# iomux_secure register map
Vendor: Texas Instruments
Peripheral module from a debugger description file (folder CC35X1).
Registers are 32-bit, access per field, reset 0x0 unless marked. A register's access mark holds for its fields unless they carry their own. Offsets are as the file gives them; lines under a group give offsets from that group; [hi:lo] are bit positions; {n}, {i} and the like mark numbered series; 'fields as' and 'values as' point back to an identical list; <NAME> marks a mode.

## iomux_secure (part 1 of 2)
0x00 ctl0_slow_clock_in reset 0x800 — CFG register for IO SLOW_CLOCK_IN. This register configures the corresponding pad
  [11] IE rw — This field enables the receiver operation from the pad
    0=DISABLE (Disable the receiver operation); 1=ENABLE (Enable the receiver operation)
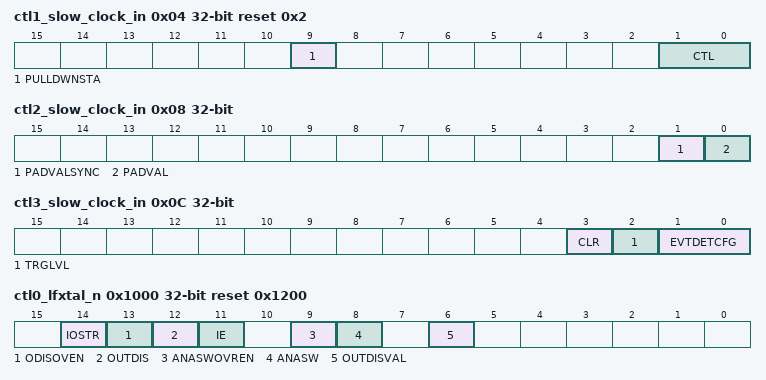
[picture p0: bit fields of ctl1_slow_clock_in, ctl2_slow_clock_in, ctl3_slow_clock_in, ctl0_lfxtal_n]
0x04 ctl1_slow_clock_in reset 0x2 — Pull control register of IO SLOW_CLOCK_IN This register configures the pull control
  [9] PULLDWNSTA ro — This field gives the IO pull down level status
    0=CLEAR (Pull disabled); 1=SET (Pull down)
  [1:0] CTL rw — The fields defines the pull control
    0=IPCTRL (IP Pull Control); 2=UP (Pull up); 3=DISABLE (Pull disable)
0x08 ctl2_slow_clock_in ro — Control register of IO SLOW_CLOCK_IN This register controls the IO state
  [1] PADVALSYNC — This field captures the synchronized(to SOC clock) received value
  [0] PADVAL — This field captures the received value from pad
0x0C ctl3_slow_clock_in — Event control register for IO SLOW_CLOCK_IN This register controls the Event configuration and behavior
  [3] CLR wo — This bit is to be used to generate CLR pulse for the event
    0=NOEFF (No effect); 1=CLEAR (Clear the event)
  [2] TRGLVL rw — This field configures the io event polarity. This field is applicable only when [EVTDETCFG] is configured LEVEL
    0=HIGH (Non Inverted polarity); 1=LOW (Inverted polarity)
  [1:0] EVTDETCFG rw — This field is to be configured to define the IO detection method
    0=MASK (Masking the event); 1=POS_EDGE (Rising edge/Positive edge detection); 2=NEG_EDGE (Falling edge/Negative edge detection); 3=LEVEL (Level detection)
0x1000 ctl0_lfxtal_n reset 0x1200 — CFG register for IO LFXTAL_N. This register configures the corresponding pad
  [14] IOSTR rw — This field controls the IO drive strength
    0=LOW (IO drives low power); 1=HIGH (IO drives high power)
  [13] ODISOVEN rw — This field controls the [OUTDIS] override
    0=DISABLE (Disable the override); 1=ENABLE (Enable the override)
  [12] OUTDIS rw — This field configures the output from the pad Note:This field is applicable only if [OUTDISOVREN] is enabled
    1=SET (Output from the pad is disabled); 0=CLEAR (Output from the pad is enabled)
  [11] IE rw — This field enables the receiver operation from the pad
    values as ctl0_slow_clock_in.IE
  [9] ANASWOVREN rw — This field controls the analog switch override
    0=DISABLE (Analog switch is controlled by IP); 1=ENABLE (Enable override on analog switch control)
  [8] ANASW rw — This field defines the Ana switch state. If the switch is enabled, the analog signal is routed to the IO pad Note: This field is applicable when [ANASWOVREN] is enabled
    0=DISABLE (Analog switch open); 1=ENABLE (Analog switch closed)
  [6] OUTDISVAL ro — The field gives the status of [OUTDIS]
    0=CLEAR (Output is enabled); 1=SET (Output is disabled)
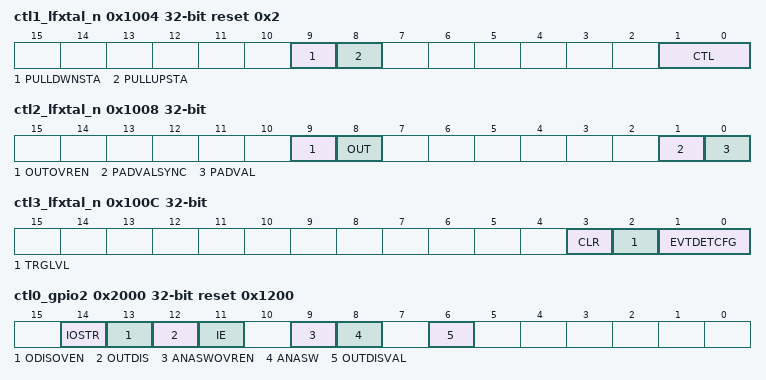
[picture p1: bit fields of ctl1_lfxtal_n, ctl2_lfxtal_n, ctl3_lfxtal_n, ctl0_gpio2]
0x1004 ctl1_lfxtal_n reset 0x2 — Pull control register of IO LFXTAL_N This register configures the pull control
  [9] PULLDWNSTA ro — This field gives the IO pull down level status
    0=CLEAR (Pull disabled); 1=SET (Pull down)
  [8] PULLUPSTA ro — This field gives the IO pull up level status
    0=CLEAR (Pull disabled); 1=SET (Pull up)
  [1:0] CTL rw — The fields defines the pull control
    0=IPCTRL (IP Pull Control); 1=DOWN (Pull down); 2=UP (Pull up); 3=DISABLE (Pull disable)
0x1008 ctl2_lfxtal_n — Control register of IO LFXTAL_N This register controls the IO state
  [9] OUTOVREN rw — This field controls the override on output
    0=DISABLE (Output controlled by IP); 1=ENABLE (Enable override on output)
  [8] OUT rw — This field configures the IO drive out value. This field is valid only when [OUTOVREN] is configured ENABLE
    0=LOW (IO drives 0); 1=HIGH (IO drives 1)
  [1] PADVALSYNC ro — This field captures the synchronized(to SOC clock) received value
  [0] PADVAL ro — This field captures the received value from pad
0x100C ctl3_lfxtal_n — Event control register for IO LFXTAL_N This register controls the Event configuration and behavior
  fields as ctl3_slow_clock_in
0x2000 ctl0_gpio2 reset 0x1200 — CFG register for IO GPIO2. This register configures the corresponding pad
  [14] IOSTR rw — This field controls the IO drive strength
    0=LOW (IO drives low power); 1=HIGH (IO drives high power)
  [13] ODISOVEN rw — This field controls the [OUTDIS] override
    values as ctl0_lfxtal_n.ODISOVEN
  [12] OUTDIS rw — This field configures the output from the pad Note:This field is applicable only if [OUTDISOVREN] is enabled
    1=SET (Output from the pad is disabled); 0=ENABLE (Output from the pad is enabled)
  [11] IE rw — This field enables the receiver operation from the pad
    values as ctl0_slow_clock_in.IE
  [9] ANASWOVREN rw — This field controls the analog switch override
    values as ctl0_lfxtal_n.ANASWOVREN
  [8] ANASW rw — This field defines the Ana switch state. If the switch is enabled, the analog signal is routed to the IO pad Note: This field is applicable when [ANASWOVREN] is enabled
    values as ctl0_lfxtal_n.ANASW
  [6] OUTDISVAL ro — The field gives the status of [OUTDIS]
    0=CLEAR (Output is enabled); 1=SET (Output is disabled)
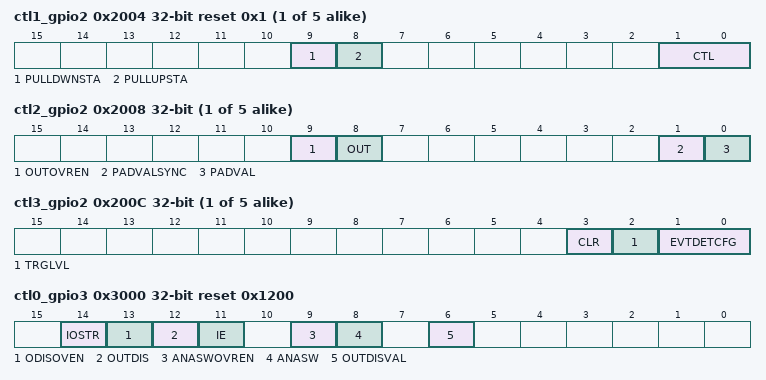
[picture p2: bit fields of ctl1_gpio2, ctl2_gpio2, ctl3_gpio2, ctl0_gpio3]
{0x4+0x1000*i} ctl1_gpio{i} reset 0x1 (i=2..6) — Pull control register of IO GPIO{i} This register configures the pull control
  fields as ctl1_lfxtal_n
{0x8+0x1000*i} ctl2_gpio{i} (i=2..6) — Control register of IO GPIO{i} This register controls the IO state
  fields as ctl2_lfxtal_n
{0xC+0x1000*i} ctl3_gpio{i} (i=2..6) — Event control register for IO GPIO{i} This register controls the Event configuration and behavior
  fields as ctl3_slow_clock_in
0x3000 ctl0_gpio3 reset 0x1200 — CFG register for IO GPIO3. This register configures the corresponding pad
  fields as ctl0_lfxtal_n
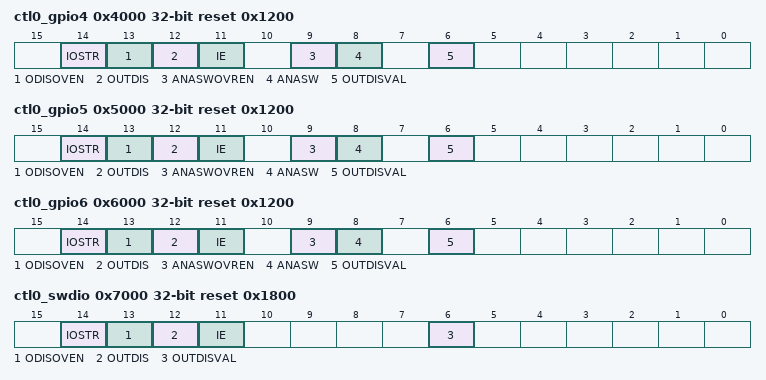
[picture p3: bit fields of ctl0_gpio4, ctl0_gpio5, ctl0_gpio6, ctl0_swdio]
0x4000 ctl0_gpio4 reset 0x1200 — CFG register for IO GPIO4. This register configures the corresponding pad
  [14] IOSTR rw — This field controls the IO drive strength
    0=LOW (IO drives low power); 1=HIGH (IO drives high power)
  [13] ODISOVEN rw — This field controls the [OUTDIS] override
    values as ctl0_lfxtal_n.ODISOVEN
  [12] OUTDIS rw — This field configures the output from the pad Note:This field is applicable only if [OUTDISOVREN] is enabled
    1=DISABLE (Output from the pad is disabled); 0=ENABLE (Output from the pad is enabled)
  [11] IE rw — This field enables the receiver operation from the pad
    values as ctl0_slow_clock_in.IE
  [9] ANASWOVREN rw — This field controls the analog switch override
    values as ctl0_lfxtal_n.ANASWOVREN
  [8] ANASW rw — This field defines the Ana switch state. If the switch is enabled, the analog signal is routed to the IO pad Note: This field is applicable when [ANASWOVREN] is enabled
    values as ctl0_lfxtal_n.ANASW
  [6] OUTDISVAL ro — The field gives the status of [OUTDIS]
    0=CLEAR (Output is enabled); 1=SET (Output is disabled)
0x5000 ctl0_gpio5 reset 0x1200 — CFG register for IO GPIO5. This register configures the corresponding pad
  fields as ctl0_lfxtal_n
0x6000 ctl0_gpio6 reset 0x1200 — CFG register for IO GPIO6. This register configures the corresponding pad
  fields as ctl0_lfxtal_n
0x7000 ctl0_swdio reset 0x1800 — CFG register for IO SWDIO. This register configures the corresponding pad
  [14] IOSTR rw — This field controls the IO drive strength
    0=LOW (IO drives low power); 1=HIGH (IO drives high power)
  [13] ODISOVEN rw — This field controls the [OUTDIS] override
    values as ctl0_lfxtal_n.ODISOVEN
  [12] OUTDIS rw — This field configures the output from the pad Note:This field is applicable only if [OUTDISOVREN] is enabled
    values as ctl0_lfxtal_n.OUTDIS
  [11] IE rw — This field enables the receiver operation from the pad
    values as ctl0_slow_clock_in.IE
  [6] OUTDISVAL ro — The field gives the status of [OUTDIS]
    0=CLEAR (Output is enabled); 1=SET (Output is disabled)
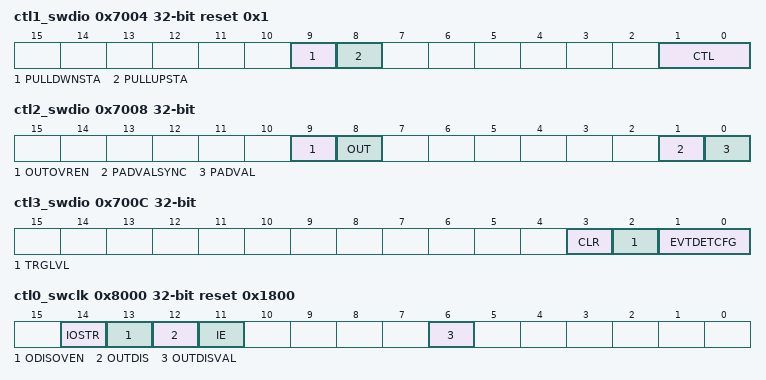
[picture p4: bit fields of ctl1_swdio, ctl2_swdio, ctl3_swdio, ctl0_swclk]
0x7004 ctl1_swdio reset 0x1 — Pull control register of IO SWDIO This register configures the pull control
  fields as ctl1_lfxtal_n
0x7008 ctl2_swdio — Control register of IO SWDIO This register controls the IO state
  fields as ctl2_lfxtal_n
0x700C ctl3_swdio — Event control register for IO SWDIO This register controls the Event configuration and behavior
  fields as ctl3_slow_clock_in
0x8000 ctl0_swclk reset 0x1800 — CFG register for IO SWCLK. This register configures the corresponding pad
  [14] IOSTR rw — This field controls the IO drive strength
    0=LOW (IO drives low power); 1=HIGH (IO drives high power)
  [13] ODISOVEN rw — This field controls the [OUTDIS] override
    values as ctl0_lfxtal_n.ODISOVEN
  [12] OUTDIS rw — This field configures the output from the pad Note:This field is applicable only if [OUTDISOVREN] is enabled
    values as ctl0_gpio4.OUTDIS
  [11] IE rw — This field enables the receiver operation from the pad
    values as ctl0_slow_clock_in.IE
  [6] OUTDISVAL ro — The field gives the status of [OUTDIS]
    0=SET (Output is enabled); 1=CLEAR (Output is disabled)
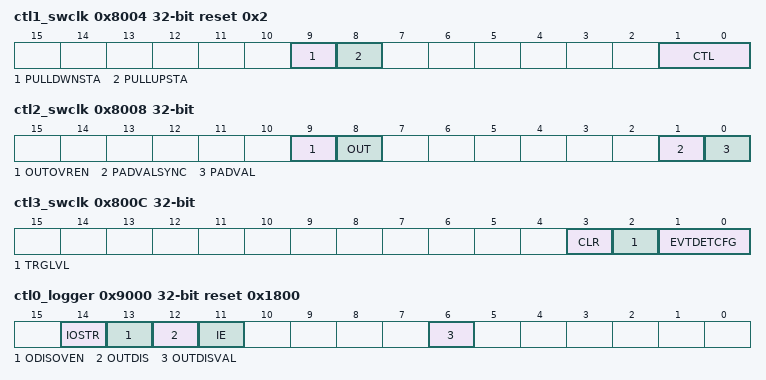
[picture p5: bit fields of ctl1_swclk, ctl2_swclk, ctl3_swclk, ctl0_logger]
0x8004 ctl1_swclk reset 0x2 — Pull control register of IO SWCLK This register configures the pull control
  fields as ctl1_lfxtal_n
0x8008 ctl2_swclk — Control register of IO SWCLK This register controls the IO state
  fields as ctl2_lfxtal_n
0x800C ctl3_swclk — Event control register for IO SWCLK This register controls the Event configuration and behavior
  fields as ctl3_slow_clock_in
0x9000 ctl0_logger reset 0x1800 — CFG register for IO LOGGER. This register configures the corresponding pad
  fields as ctl0_swdio
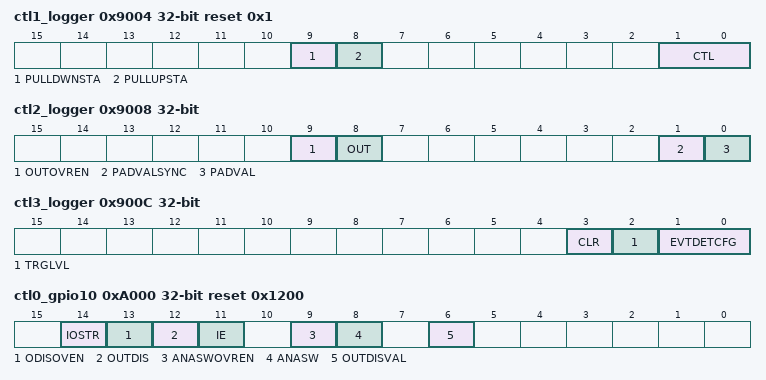
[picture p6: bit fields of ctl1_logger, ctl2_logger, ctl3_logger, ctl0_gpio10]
0x9004 ctl1_logger reset 0x1 — Pull control register of IO LOGGER This register configures the pull control
  fields as ctl1_lfxtal_n
0x9008 ctl2_logger — Control register of IO LOGGER This register controls the IO state
  fields as ctl2_lfxtal_n
0x900C ctl3_logger — Event control register for IO LOGGER This register controls the Event configuration and behavior
  fields as ctl3_slow_clock_in
0xA000 ctl0_gpio10 reset 0x1200 — CFG register for IO GPIO10. This register configures the corresponding pad
  fields as ctl0_lfxtal_n
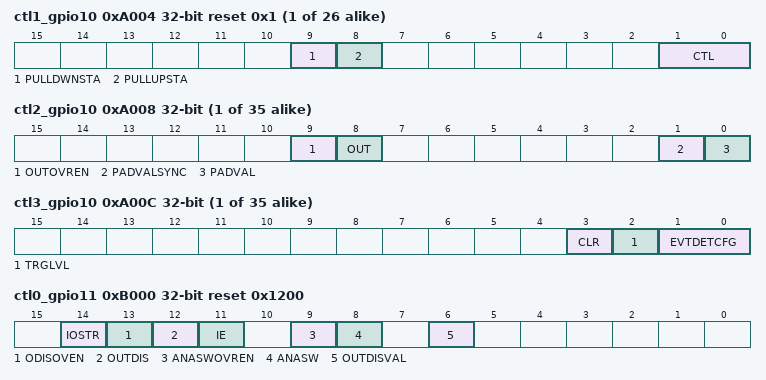
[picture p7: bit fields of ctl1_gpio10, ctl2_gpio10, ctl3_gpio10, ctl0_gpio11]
{0x4+0x1000*i} ctl1_gpio{i} reset 0x1 (i=10..35) — Pull control register of IO GPIO{i} This register configures the pull control
  fields as ctl1_lfxtal_n
{0x8+0x1000*i} ctl2_gpio{i} (i=10..44) — Control register of IO GPIO{i} This register controls the IO state
  fields as ctl2_lfxtal_n
{0xC+0x1000*i} ctl3_gpio{i} (i=10..44) — Event control register for IO GPIO{i} This register controls the Event configuration and behavior
  fields as ctl3_slow_clock_in
0xB000 ctl0_gpio11 reset 0x1200 — CFG register for IO GPIO11. This register configures the corresponding pad
  fields as ctl0_lfxtal_n
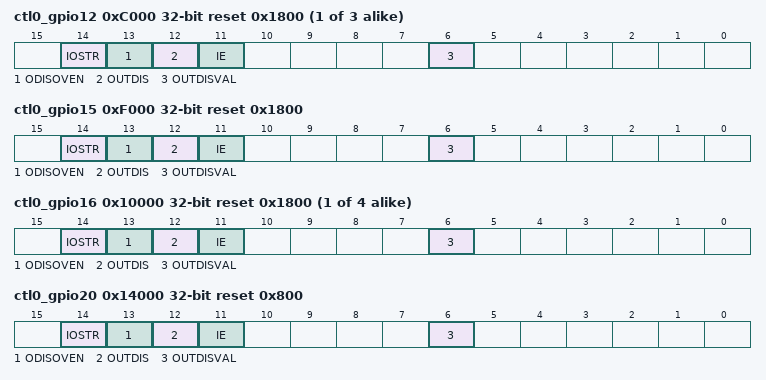
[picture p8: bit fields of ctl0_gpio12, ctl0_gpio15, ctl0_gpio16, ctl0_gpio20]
{0x0+0x1000*i} ctl0_gpio{i} reset 0x1800 (i=12..14) — CFG register for IO GPIO{i}. This register configures the corresponding pad
  fields as ctl0_swdio
0xF000 ctl0_gpio15 reset 0x1800 — CFG register for IO GPIO15. This register configures the corresponding pad
  [14] IOSTR rw — This field controls the IO drive strength
    0=LOW (IO drives low power); 1=HIGH (IO drives high power)
  [13] ODISOVEN rw — This field controls the [OUTDIS] override
    values as ctl0_lfxtal_n.ODISOVEN
  [12] OUTDIS rw — This field configures the output from the pad Note:This field is applicable only if [OUTDISOVREN] is enabled
    values as ctl0_lfxtal_n.OUTDIS
  [11] IE rw — This field enables the receiver operation from the pad
    values as ctl0_slow_clock_in.IE
  [6] OUTDISVAL ro — The field gives the status of [OUTDIS]
    0=SET (Output is enabled); 1=CLEAR (Output is disabled)
{0x0+0x1000*i} ctl0_gpio{i} reset 0x1800 (i=16..19) — CFG register for IO GPIO{i}. This register configures the corresponding pad
  fields as ctl0_swdio
0x14000 ctl0_gpio20 reset 0x800 — CFG register for IO GPIO20. This register configures the corresponding pad
  fields as ctl0_swdio
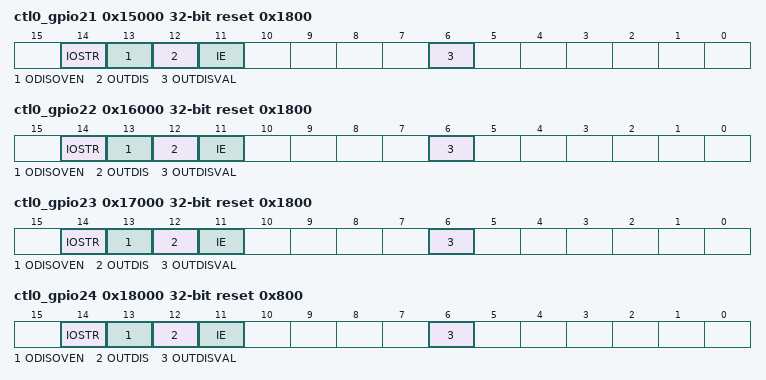
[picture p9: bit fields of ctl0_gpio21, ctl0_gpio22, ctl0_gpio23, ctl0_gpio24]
0x15000 ctl0_gpio21 reset 0x1800 — CFG register for IO GPIO21. This register configures the corresponding pad
  fields as ctl0_swdio
0x16000 ctl0_gpio22 reset 0x1800 — CFG register for IO GPIO22. This register configures the corresponding pad
  fields as ctl0_swclk
0x17000 ctl0_gpio23 reset 0x1800 — CFG register for IO GPIO23. This register configures the corresponding pad
  fields as ctl0_swdio
0x18000 ctl0_gpio24 reset 0x800 — CFG register for IO GPIO24. This register configures the corresponding pad
  fields as ctl0_swdio
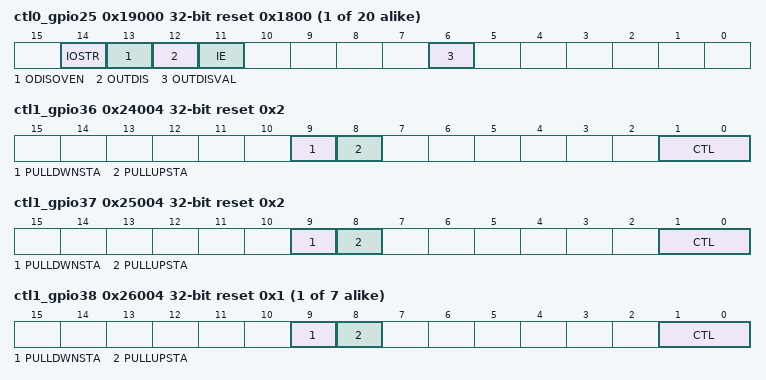
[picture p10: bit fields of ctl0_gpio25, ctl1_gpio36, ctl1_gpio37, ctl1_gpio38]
{0x0+0x1000*i} ctl0_gpio{i} reset 0x1800 (i=25..44) — CFG register for IO GPIO{i}. This register configures the corresponding pad
  fields as ctl0_swdio
0x24004 ctl1_gpio36 reset 0x2 — Pull control register of IO GPIO36 This register configures the pull control
  fields as ctl1_lfxtal_n
0x25004 ctl1_gpio37 reset 0x2 — Pull control register of IO GPIO37 This register configures the pull control
  fields as ctl1_lfxtal_n
{0x4+0x1000*i} ctl1_gpio{i} reset 0x1 (i=38..44) — Pull control register of IO GPIO{i} This register configures the pull control
  fields as ctl1_lfxtal_n
0x2D000 sop_dis — This register disables the SOP overrides when the device was powered in one of the SoP modes.
  [0] SOPDIS rw — The field is to disable SOP
    1=DISABLE (Disable SOP); 0=USE (Use SOP)
0x2D004 ctl_common_slow_clock_in — Port configuration register for IO SLOW_CLOCK_IN
  [4:0] IOSEL rw — Pinmux selection Control Mode can be used to select the IO functionality or drive 0/1/Hi-Z sel 5'd2 -- wifi_gpio_0 sel 5'd9 -- gpt1_1 sel 5'd10 -- gpt0_1
    0=SEL_0 (reserved); 1=SEL_1 (reserved); 2=SEL_2 (wifi_gpio_0); {v}=SEL_{v} (reserved) (v=3..8); 9=SEL_9 (gpt1_1); 10=SEL_10 (gpt0_1); {v}=SEL_{v} (reserved) (v=11..31)
0x2D008 ctl_common_lfxtal_n — Port configuration register for IO LFXTAL_N
  [4:0] IOSEL rw — Pinmux selection Control Mode can be used to select the IO functionality or drive 0/1/Hi-Z sel 5'd0 -- lfxt_n sel 5'd2 -- wifi_gpio_1 sel 5'd7 -- gpt1_pre_event sel 5'd8 -- gpt0_pre_event sel 5'd9 -- gpt1_0 sel 5'd10 -- gpt0_0 sel 5'd11 -- gpt_infrared sel 5'd19 -- sdio_oob_irq sel 5'd20 -- coex_grant sel 5'd23 -- ant_sel_0
    0=SEL_0 (lfxt_n); 1=SEL_1 (reserved); 2=SEL_2 (wifi_gpio_1); {v}=SEL_{v} (reserved) (v=3..6); 7=SEL_7 (gpt1_pre_event); 8=SEL_8 (gpt0_pre_event); 9=SEL_9 (gpt1_0); 10=SEL_10 (gpt0_0); 11=SEL_11 (gpt_infrared); {v}=SEL_{v} (reserved) (v=12..18); 19=SEL_19 (sdio_oob_irq); 20=SEL_20 (coex_grant); 21=SEL_21 (reserved); 22=SEL_22 (reserved); 23=SEL_23 (ant_sel_0); {v}=SEL_{v} (reserved) (v=24..31)
0x2D00C ctl_common_gpio2 — Port configuration register for IO GPIO2
  [4:0] IOSEL rw — Pinmux selection Control Mode can be used to select the IO functionality or drive 0/1/Hi-Z sel 5'd1 -- xspi_reset_ram sel 5'd2 -- wifi_gpio_2 sel 5'd3 -- sdio_mmc_cd sel 5'd6 -- i2c1_clk sel 5'd9 -- gpt1_3 sel 5'd10 -- dcan_tx sel 5'd11 -- wake_observe_bus_6 sel 5'd12 -- debug_bus_4 sel 5'd16 -- spi0_cs4 sel 5'd18 -- gpt1_pre_event sel 5'd19 -- sdio_oob_irq sel 5'd20 -- coex_grant sel 5'd21 -- coex_req sel 5'd22 -- ble_rftrc sel 5'd23 -- ant_sel_2 sel 5'd24 -- cca sel 5'd26 -- trclk
    0=SEL_0 (reserved); 1=SEL_1 (xspi_reset_ram); 2=SEL_2 (wifi_gpio_2); 3=SEL_3 (sdio_mmc_cd); 4=SEL_4 (reserved); 5=SEL_5 (reserved); 6=SEL_6 (i2c1_clk); 7=SEL_7 (reserved); 8=SEL_8 (reserved); 9=SEL_9 (gpt1_3); 10=SEL_10 (dcan_tx); 11=SEL_11 (wake_observe_bus_6); 12=SEL_12 (debug_bus_4); 13=SEL_13 (reserved); 14=SEL_14 (reserved); 15=SEL_15 (reserved); 16=SEL_16 (spi0_cs4); 17=SEL_17 (reserved); 18=SEL_18 (gpt1_pre_event); 19=SEL_19 (sdio_oob_irq); 20=SEL_20 (coex_grant); 21=SEL_21 (coex_req); 22=SEL_22 (ble_rftrc); 23=SEL_23 (ant_sel_2); 24=SEL_24 (cca); 25=SEL_25 (reserved); 26=SEL_26 (trclk); {v}=SEL_{v} (reserved) (v=27..31)
0x2D010 ctl_common_gpio3 — Port configuration register for IO GPIO3
  [4:0] IOSEL rw — Pinmux selection Control Mode can be used to select the IO functionality or drive 0/1/Hi-Z sel 5'd1 -- uart1_tx sel 5'd2 -- wifi_gpio_3 sel 5'd3 -- sdio_mmc_wp sel 5'd4 -- spi1_clk sel 5'd5 -- uart1_rts sel 5'd6 -- i2s_mclk sel 5'd7 -- i2s_data0 sel 5'd8 -- pdm_data1 sel 5'd9 -- gpt1_0 sel 5'd10 -- dcan_rx sel 5'd11 -- wake_observe_bus_7 sel 5'd12 -- debug_bus_0 sel 5'd16 -- spi0_cs3 sel 5'd17 -- xspi_cs_ram sel 5'd18 -- gpt1_1_n sel 5'd19 -- sdio_clk sel 5'd20 -- coex_req sel 5'd21 -- gpt0_0_n sel 5'd22 -- gpt_infrared sel 5'd23 -- ant_sel_3 sel 5'd24 -- ble_rfc_gpo_7 sel 5'd25 -- swo_m3 sel 5'd27 -- swo_m33
    0=SEL_0 (reserved); 1=SEL_1 (uart1_tx); 2=SEL_2 (wifi_gpio_3); 3=SEL_3 (sdio_mmc_wp); 4=SEL_4 (spi1_clk); 5=SEL_5 (uart1_rts); 6=SEL_6 (i2s_mclk); 7=SEL_7 (i2s_data0); 8=SEL_8 (pdm_data1); 9=SEL_9 (gpt1_0); 10=SEL_10 (dcan_rx); 11=SEL_11 (wake_observe_bus_7); 12=SEL_12 (debug_bus_0); 13=SEL_13 (reserved); 14=SEL_14 (reserved); 15=SEL_15 (reserved); 16=SEL_16 (spi0_cs3); 17=SEL_17 (xspi_cs_ram); 18=SEL_18 (gpt1_1_n); 19=SEL_19 (sdio_clk); 20=SEL_20 (coex_req); 21=SEL_21 (gpt0_0_n); 22=SEL_22 (gpt_infrared); 23=SEL_23 (ant_sel_3); 24=SEL_24 (ble_rfc_gpo_7); 25=SEL_25 (swo_m3); 26=SEL_26 (reserved); 27=SEL_27 (swo_m33); {v}=SEL_{v} (reserved) (v=28..31)
0x2D014 ctl_common_gpio4 — Port configuration register for IO GPIO4
  [4:0] IOSEL rw — Pinmux selection Control Mode can be used to select the IO functionality or drive 0/1/Hi-Z sel 5'd1 -- uart1_rx sel 5'd2 -- wifi_gpio_4 sel 5'd3 -- sdio_mmc_cd sel 5'd4 -- spi1_cs1 sel 5'd5 -- uart1_cts sel 5'd6 -- i2s_bclk sel 5'd7 -- i2s_data1 sel 5'd8 -- pdm_bclk sel 5'd9 -- gpt1_1 sel 5'd10 -- dcan_tx sel 5'd11 -- wake_observe_bus_8 sel 5'd12 -- debug_bus_1 sel 5'd16 -- spi0_cs2 sel 5'd17 -- ext_clk sel 5'd18 -- gpt1_0_n sel 5'd19 -- sdio_cmd sel 5'd20 -- coex_priority sel 5'd21 -- gpt0_1_n sel 5'd24 -- ble_rfc_gpo_6
    0=SEL_0 (reserved); 1=SEL_1 (uart1_rx); 2=SEL_2 (wifi_gpio_4); 3=SEL_3 (sdio_mmc_cd); 4=SEL_4 (spi1_cs1); 5=SEL_5 (uart1_cts); 6=SEL_6 (i2s_bclk); 7=SEL_7 (i2s_data1); 8=SEL_8 (pdm_bclk); 9=SEL_9 (gpt1_1); 10=SEL_10 (dcan_tx); 11=SEL_11 (wake_observe_bus_8); 12=SEL_12 (debug_bus_1); 13=SEL_13 (reserved); 14=SEL_14 (reserved); 15=SEL_15 (reserved); 16=SEL_16 (spi0_cs2); 17=SEL_17 (ext_clk); 18=SEL_18 (gpt1_0_n); 19=SEL_19 (sdio_cmd); 20=SEL_20 (coex_priority); 21=SEL_21 (gpt0_1_n); 22=SEL_22 (reserved); 23=SEL_23 (reserved); 24=SEL_24 (ble_rfc_gpo_6); {v}=SEL_{v} (reserved) (v=25..31)
0x2D018 ctl_common_gpio5 — Port configuration register for IO GPIO5
  [4:0] IOSEL rw — Pinmux selection Control Mode can be used to select the IO functionality or drive 0/1/Hi-Z sel 5'd1 -- xspi_reset_ram sel 5'd2 -- wifi_gpio_5 sel 5'd3 -- sdio_mmc_pow2 sel 5'd4 -- spi1_miso sel 5'd5 -- uart1_tx sel 5'd6 -- i2c0_clk sel 5'd7 -- i2s_mclk sel 5'd8 -- pdm_bclk sel 5'd9 -- gpt1_2 sel 5'd10 -- dcan_tx sel 5'd11 -- jtag_tdi sel 5'd12 -- debug_bus_11 sel 5'd16 -- spi0_cs4 sel 5'd17 -- ext_clk sel 5'd18 -- gpt1_0_n sel 5'd19 -- sdio_d0 sel 5'd20 -- coex_req sel 5'd21 -- gpt0_2_n sel 5'd22 -- ble_rftrc sel 5'd23 -- ant_sel_1 sel 5'd25 -- ble_rfc_gpi_2 sel 5'd28 -- i2c1_data
    0=SEL_0 (reserved); 1=SEL_1 (xspi_reset_ram); 2=SEL_2 (wifi_gpio_5); 3=SEL_3 (sdio_mmc_pow2); 4=SEL_4 (spi1_miso); 5=SEL_5 (uart1_tx); 6=SEL_6 (i2c0_clk); 7=SEL_7 (i2s_mclk); 8=SEL_8 (pdm_bclk); 9=SEL_9 (gpt1_2); 10=SEL_10 (dcan_tx); 11=SEL_11 (jtag_tdi); 12=SEL_12 (debug_bus_11); 13=SEL_13 (reserved); 14=SEL_14 (reserved); 15=SEL_15 (reserved); 16=SEL_16 (spi0_cs4); 17=SEL_17 (ext_clk); 18=SEL_18 (gpt1_0_n); 19=SEL_19 (sdio_d0); 20=SEL_20 (coex_req); 21=SEL_21 (gpt0_2_n); 22=SEL_22 (ble_rftrc); 23=SEL_23 (ant_sel_1); 24=SEL_24 (reserved); 25=SEL_25 (ble_rfc_gpi_2); 26=SEL_26 (reserved); 27=SEL_27 (reserved); 28=SEL_28 (i2c1_data); 29=SEL_29 (reserved); 30=SEL_30 (reserved); 31=SEL_31 (reserved)
0x2D01C ctl_common_gpio6 — Port configuration register for IO GPIO6
  [4:0] IOSEL rw — Pinmux selection Control Mode can be used to select the IO functionality or drive 0/1/Hi-Z sel 5'd1 -- xspi_cs_ram sel 5'd2 -- wifi_gpio_6 sel 5'd3 -- sdio_mmc_pow1 sel 5'd4 -- spi1_mosi sel 5'd5 -- uart1_rx sel 5'd6 -- i2c0_data sel 5'd7 -- i2s_wclk sel 5'd8 -- pdm_data0 sel 5'd9 -- gpt1_3 sel 5'd10 -- dcan_rx sel 5'd11 -- sdio_mmc_wp sel 5'd12 -- debug_bus_12 sel 5'd16 -- spi0_cs4 sel 5'd17 -- i2s_bclk sel 5'd18 -- gpt1_1_n sel 5'd19 -- sdio_d1 sel 5'd20 -- coex_priority sel 5'd21 -- gpt0_3_n sel 5'd22 -- gpt1_pre_event sel 5'd23 -- ant_sel_0 sel 5'd24 -- cca sel 5'd25 -- ble_rfc_gpi_3 sel 5'd26 -- coex_grant sel 5'd28 -- i2c1_clk sel 5'd29 -- sdio_mmc_pow2
    0=SEL_0 (reserved); 1=SEL_1 (xspi_cs_ram); 2=SEL_2 (wifi_gpio_6); 3=SEL_3 (sdio_mmc_pow1); 4=SEL_4 (spi1_mosi); 5=SEL_5 (uart1_rx); 6=SEL_6 (i2c0_data); 7=SEL_7 (i2s_wclk); 8=SEL_8 (pdm_data0); 9=SEL_9 (gpt1_3); 10=SEL_10 (dcan_rx); 11=SEL_11 (sdio_mmc_wp); 12=SEL_12 (debug_bus_12); 13=SEL_13 (reserved); 14=SEL_14 (reserved); 15=SEL_15 (reserved); 16=SEL_16 (spi0_cs4); 17=SEL_17 (i2s_bclk); 18=SEL_18 (gpt1_1_n); 19=SEL_19 (sdio_d1); 20=SEL_20 (coex_priority); 21=SEL_21 (gpt0_3_n); 22=SEL_22 (gpt1_pre_event); 23=SEL_23 (ant_sel_0); 24=SEL_24 (cca); 25=SEL_25 (ble_rfc_gpi_3); 26=SEL_26 (coex_grant); 27=SEL_27 (reserved); 28=SEL_28 (i2c1_clk); 29=SEL_29 (sdio_mmc_pow2); 30=SEL_30 (reserved); 31=SEL_31 (reserved)
0x2D020 ctl_common_swdio — Port configuration register for IO SWDIO
  [4:0] IOSEL rw — Pinmux selection Control Mode can be used to select the IO functionality or drive 0/1/Hi-Z sel 5'd0 -- swdio sel 5'd2 -- wifi_gpio_7 sel 5'd3 -- sdio_mmc_pow2 sel 5'd4 -- jtag_tms sel 5'd23 -- ant_sel_0
    0=SEL_0 (swdio); 1=SEL_1 (reserved); 2=SEL_2 (wifi_gpio_7); 3=SEL_3 (sdio_mmc_pow2); 4=SEL_4 (jtag_tms); {v}=SEL_{v} (reserved) (v=5..22); 23=SEL_23 (ant_sel_0); {v}=SEL_{v} (reserved) (v=24..31)
0x2D024 ctl_common_swclk — Port configuration register for IO SWCLK
  [4:0] IOSEL rw — Pinmux selection Control Mode can be used to select the IO functionality or drive 0/1/Hi-Z sel 5'd0 -- swclk sel 5'd2 -- wifi_gpio_8 sel 5'd3 -- sdio_mmc_pow1 sel 5'd4 -- jtag_tck sel 5'd23 -- ant_sel_1
    0=SEL_0 (swclk); 1=SEL_1 (reserved); 2=SEL_2 (wifi_gpio_8); 3=SEL_3 (sdio_mmc_pow1); 4=SEL_4 (jtag_tck); {v}=SEL_{v} (reserved) (v=5..22); 23=SEL_23 (ant_sel_1); {v}=SEL_{v} (reserved) (v=24..31)
0x2D028 ctl_common_logger — Port configuration register for IO LOGGER
  [4:0] IOSEL rw — Pinmux selection Control Mode can be used to select the IO functionality or drive 0/1/Hi-Z sel 5'd1 -- logger sel 5'd2 -- wifi_gpio_9 sel 5'd3 -- sdio_mmc_cd sel 5'd4 -- ble_rftrc sel 5'd11 -- jtag_tdo sel 5'd23 -- ant_sel_2 sel 5'd26 -- swo_m3 sel 5'd27 -- swo_m33
    0=SEL_0 (reserved); 1=SEL_1 (logger); 2=SEL_2 (wifi_gpio_9); 3=SEL_3 (sdio_mmc_cd); 4=SEL_4 (ble_rftrc); {v}=SEL_{v} (reserved) (v=5..10); 11=SEL_11 (jtag_tdo); {v}=SEL_{v} (reserved) (v=12..22); 23=SEL_23 (ant_sel_2); 24=SEL_24 (reserved); 25=SEL_25 (reserved); 26=SEL_26 (swo_m3); 27=SEL_27 (swo_m33); {v}=SEL_{v} (reserved) (v=28..31)
0x2D02C ctl_common_gpio10 — Port configuration register for IO GPIO10
  [4:0] IOSEL rw — Pinmux selection Control Mode can be used to select the IO functionality or drive 0/1/Hi-Z sel 5'd1 -- uart1_tx sel 5'd2 -- wifi_gpio_10 sel 5'd3 -- sdio_mmc_data_3 sel 5'd4 -- spi1_clk sel 5'd5 -- uart1_rts sel 5'd6 -- i2c1_data sel 5'd7 -- i2s_data1 sel 5'd8 -- pdm_data1 sel 5'd9 -- gpt1_0 sel 5'd10 -- dcan_rx sel 5'd11 -- uart_rs232_rx sel 5'd12 -- debug_bus_10 sel 5'd16 -- spi0_cs3 sel 5'd18 -- gpt1_3_n sel 5'd19 -- sdio_d3 sel 5'd20 -- coex_priority sel 5'd21 -- coex_grant sel 5'd23 -- ant_sel_2 sel 5'd24 -- cca sel 5'd25 -- ble_rfc_gpi_1 sel 5'd26 -- trdata_0
    0=SEL_0 (reserved); 1=SEL_1 (uart1_tx); 2=SEL_2 (wifi_gpio_10); 3=SEL_3 (sdio_mmc_data_3); 4=SEL_4 (spi1_clk); 5=SEL_5 (uart1_rts); 6=SEL_6 (i2c1_data); 7=SEL_7 (i2s_data1); 8=SEL_8 (pdm_data1); 9=SEL_9 (gpt1_0); 10=SEL_10 (dcan_rx); 11=SEL_11 (uart_rs232_rx); 12=SEL_12 (debug_bus_10); 13=SEL_13 (reserved); 14=SEL_14 (reserved); 15=SEL_15 (reserved); 16=SEL_16 (spi0_cs3); 17=SEL_17 (reserved); 18=SEL_18 (gpt1_3_n); 19=SEL_19 (sdio_d3); 20=SEL_20 (coex_priority); 21=SEL_21 (coex_grant); 22=SEL_22 (reserved); 23=SEL_23 (ant_sel_2); 24=SEL_24 (cca); 25=SEL_25 (ble_rfc_gpi_1); 26=SEL_26 (trdata_0); {v}=SEL_{v} (reserved) (v=27..31)
0x2D030 ctl_common_gpio11 — Port configuration register for IO GPIO11
  [4:0] IOSEL rw — Pinmux selection Control Mode can be used to select the IO functionality or drive 0/1/Hi-Z sel 5'd1 -- uart1_rx sel 5'd2 -- wifi_gpio_11 sel 5'd3 -- sdio_mmc_data_2 sel 5'd4 -- spi1_cs1 sel 5'd5 -- uart1_cts sel 5'd6 -- i2c1_clk sel 5'd7 -- i2s_data0 sel 5'd8 -- pdm_data0 sel 5'd9 -- gpt1_1 sel 5'd10 -- dcan_tx sel 5'd11 -- uart_rs232_tx sel 5'd12 -- debug_bus_9 sel 5'd16 -- spi0_cs2 sel 5'd17 -- ext_clk sel 5'd18 -- gpt1_2_n sel 5'd19 -- sdio_d2 sel 5'd20 -- coex_req sel 5'd23 -- ant_sel_3 sel 5'd24 -- cca sel 5'd25 -- swo_m3 sel 5'd26 -- trdata_1
    0=SEL_0 (reserved); 1=SEL_1 (uart1_rx); 2=SEL_2 (wifi_gpio_11); 3=SEL_3 (sdio_mmc_data_2); 4=SEL_4 (spi1_cs1); 5=SEL_5 (uart1_cts); 6=SEL_6 (i2c1_clk); 7=SEL_7 (i2s_data0); 8=SEL_8 (pdm_data0); 9=SEL_9 (gpt1_1); 10=SEL_10 (dcan_tx); 11=SEL_11 (uart_rs232_tx); 12=SEL_12 (debug_bus_9); 13=SEL_13 (reserved); 14=SEL_14 (reserved); 15=SEL_15 (reserved); 16=SEL_16 (spi0_cs2); 17=SEL_17 (ext_clk); 18=SEL_18 (gpt1_2_n); 19=SEL_19 (sdio_d2); 20=SEL_20 (coex_req); 21=SEL_21 (reserved); 22=SEL_22 (reserved); 23=SEL_23 (ant_sel_3); 24=SEL_24 (cca); 25=SEL_25 (swo_m3); 26=SEL_26 (trdata_1); {v}=SEL_{v} (reserved) (v=27..31)
0x2D034 ctl_common_gpio12 — Port configuration register for IO GPIO12
  [4:0] IOSEL rw — Pinmux selection Control Mode can be used to select the IO functionality or drive 0/1/Hi-Z sel 5'd2 -- wifi_gpio_12 sel 5'd3 -- sdio_mmc_data_1 sel 5'd4 -- spi1_cs1 sel 5'd5 -- uart1_rts sel 5'd6 -- uart0_rts sel 5'd7 -- i2s_wclk sel 5'd9 -- gpt1_2 sel 5'd10 -- uart_rs232_tx sel 5'd11 -- jtag_tdo sel 5'd12 -- debug_bus_8 sel 5'd16 -- gpt0_pre_event sel 5'd17 -- gpt1_pre_event sel 5'd18 -- gpt1_3_n sel 5'd19 -- sdio_clk sel 5'd22 -- ble_rfc_gpo_7 sel 5'd23 -- ant_sel_1 sel 5'd25 -- ble_rfc_gpi_2 sel 5'd26 -- trdata_2
    0=SEL_0 (reserved); 1=SEL_1 (reserved); 2=SEL_2 (wifi_gpio_12); 3=SEL_3 (sdio_mmc_data_1); 4=SEL_4 (spi1_cs1); 5=SEL_5 (uart1_rts); 6=SEL_6 (uart0_rts); 7=SEL_7 (i2s_wclk); 8=SEL_8 (reserved); 9=SEL_9 (gpt1_2); 10=SEL_10 (uart_rs232_tx); 11=SEL_11 (jtag_tdo); 12=SEL_12 (debug_bus_8); 13=SEL_13 (reserved); 14=SEL_14 (reserved); 15=SEL_15 (reserved); 16=SEL_16 (gpt0_pre_event); 17=SEL_17 (gpt1_pre_event); 18=SEL_18 (gpt1_3_n); 19=SEL_19 (sdio_clk); 20=SEL_20 (reserved); 21=SEL_21 (reserved); 22=SEL_22 (ble_rfc_gpo_7); 23=SEL_23 (ant_sel_1); 24=SEL_24 (reserved); 25=SEL_25 (ble_rfc_gpi_2); 26=SEL_26 (trdata_2); {v}=SEL_{v} (reserved) (v=27..31)
0x2D038 ctl_common_gpio13 — Port configuration register for IO GPIO13
  [4:0] IOSEL rw — Pinmux selection Control Mode can be used to select the IO functionality or drive 0/1/Hi-Z sel 5'd2 -- wifi_gpio_13 sel 5'd3 -- sdio_mmc_data_0 sel 5'd4 -- spi1_mosi sel 5'd5 -- uart1_cts sel 5'd6 -- uart0_tx sel 5'd7 -- i2s_bclk sel 5'd8 -- i2s_mclk sel 5'd9 -- gpt1_3 sel 5'd11 -- wake_observe_bus_14 sel 5'd12 -- debug_bus_7 sel 5'd18 -- gpt1_2_n sel 5'd19 -- sdio_cmd sel 5'd20 -- coex_priority sel 5'd21 -- ble_rftrc sel 5'd22 -- ble_rfc_gpo_6 sel 5'd23 -- ant_sel_0 sel 5'd25 -- ble_rfc_gpi_1 sel 5'd26 -- trdata_3
    0=SEL_0 (reserved); 1=SEL_1 (reserved); 2=SEL_2 (wifi_gpio_13); 3=SEL_3 (sdio_mmc_data_0); 4=SEL_4 (spi1_mosi); 5=SEL_5 (uart1_cts); 6=SEL_6 (uart0_tx); 7=SEL_7 (i2s_bclk); 8=SEL_8 (i2s_mclk); 9=SEL_9 (gpt1_3); 10=SEL_10 (reserved); 11=SEL_11 (wake_observe_bus_14); 12=SEL_12 (debug_bus_7); {v}=SEL_{v} (reserved) (v=13..17); 18=SEL_18 (gpt1_2_n); 19=SEL_19 (sdio_cmd); 20=SEL_20 (coex_priority); 21=SEL_21 (ble_rftrc); 22=SEL_22 (ble_rfc_gpo_6); 23=SEL_23 (ant_sel_0); 24=SEL_24 (reserved); 25=SEL_25 (ble_rfc_gpi_1); 26=SEL_26 (trdata_3); {v}=SEL_{v} (reserved) (v=27..31)
0x2D03C ctl_common_gpio14 — Port configuration register for IO GPIO14
  [4:0] IOSEL rw — Pinmux selection Control Mode can be used to select the IO functionality or drive 0/1/Hi-Z sel 5'd2 -- wifi_gpio_14 sel 5'd3 -- sdio_mmc_clk sel 5'd4 -- spi1_clk sel 5'd5 -- uart1_tx sel 5'd6 -- uart0_rx sel 5'd9 -- gpt1_0 sel 5'd11 -- wake_observe_bus_15 sel 5'd12 -- debug_bus_clk sel 5'd16 -- spi0_cs2 sel 5'd17 -- gpt1_pre_event sel 5'd18 -- gpt1_1_n sel 5'd19 -- sdio_d0 sel 5'd20 -- coex_grant sel 5'd22 -- ble_rfc_gpo_4 sel 5'd24 -- ble_rfc_gpi_2 sel 5'd25 -- ble_rfc_gpi_1 sel 5'd26 -- trclk sel 5'd27 -- digital_fast_clk_in
    0=SEL_0 (reserved); 1=SEL_1 (reserved); 2=SEL_2 (wifi_gpio_14); 3=SEL_3 (sdio_mmc_clk); 4=SEL_4 (spi1_clk); 5=SEL_5 (uart1_tx); 6=SEL_6 (uart0_rx); 7=SEL_7 (reserved); 8=SEL_8 (reserved); 9=SEL_9 (gpt1_0); 10=SEL_10 (reserved); 11=SEL_11 (wake_observe_bus_15); 12=SEL_12 (debug_bus_clk); 13=SEL_13 (reserved); 14=SEL_14 (reserved); 15=SEL_15 (reserved); 16=SEL_16 (spi0_cs2); 17=SEL_17 (gpt1_pre_event); 18=SEL_18 (gpt1_1_n); 19=SEL_19 (sdio_d0); 20=SEL_20 (coex_grant); 21=SEL_21 (reserved); 22=SEL_22 (ble_rfc_gpo_4); 23=SEL_23 (reserved); 24=SEL_24 (ble_rfc_gpi_2); 25=SEL_25 (ble_rfc_gpi_1); 26=SEL_26 (trclk); 27=SEL_27 (digital_fast_clk_in); {v}=SEL_{v} (reserved) (v=28..31)
